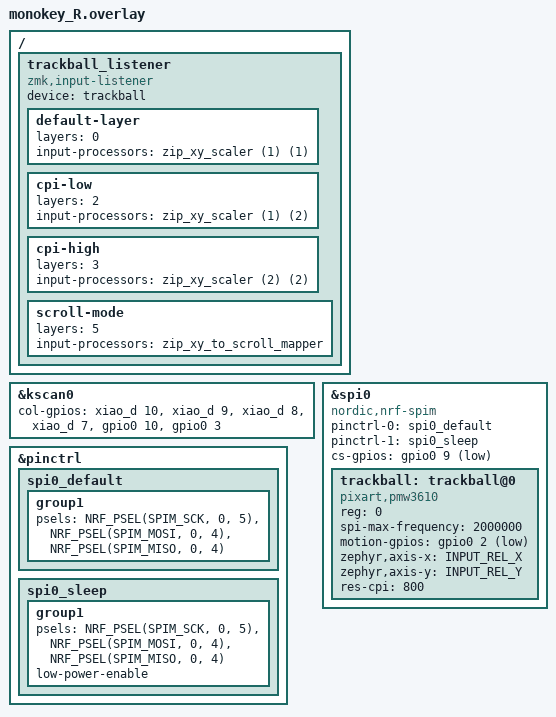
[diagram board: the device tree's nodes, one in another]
#include <zephyr/dt-bindings/input/input-event-codes.h>
#include "monokey.dtsi"

/* =========================
 * Right half: add col-gpios (required by zmk,kscan-gpio-matrix)
 * =========================
 *
 * NOTE:
 * 左側は最後の列に <&gpio0 9 ...> を使っていますが、
 * 右側はSPIトラックボールのCSに gpio0 9 を使っているため競合します。
 *
 * ここでは「ビルドを通すため」に、最後の1本だけ別ピン(gpio0 3)に退避しています。
 * もし右側キーが反応しない場合は、この gpio0 3 を"右側実配線の列ピン"へ変更してください。
 */
&kscan0 {
    col-gpios
        = <&xiao_d 10 GPIO_ACTIVE_HIGH>
        , <&xiao_d 9  GPIO_ACTIVE_HIGH>
        , <&xiao_d 8  GPIO_ACTIVE_HIGH>
        , <&xiao_d 7  GPIO_ACTIVE_HIGH>
        , <&gpio0 10  GPIO_ACTIVE_HIGH>
        , <&gpio0 3   GPIO_ACTIVE_HIGH>
        ;
};

&pinctrl {
    spi0_default: spi0_default {
        group1 {
            psels = <NRF_PSEL(SPIM_SCK, 0, 5)>,
                    <NRF_PSEL(SPIM_MOSI, 0, 4)>,
                    <NRF_PSEL(SPIM_MISO, 0, 4)>;
        };
    };

    spi0_sleep: spi0_sleep {
        group1 {
            psels = <NRF_PSEL(SPIM_SCK, 0, 5)>,
                    <NRF_PSEL(SPIM_MOSI, 0, 4)>,
                    <NRF_PSEL(SPIM_MISO, 0, 4)>;
            low-power-enable;
        };
    };
};

&spi0 {
    status = "okay";
    compatible = "nordic,nrf-spim";

    pinctrl-0 = <&spi0_default>;
    pinctrl-1 = <&spi0_sleep>;
    pinctrl-names = "default", "sleep";

    cs-gpios = <&gpio0 9 GPIO_ACTIVE_LOW>;

    trackball: trackball@0 {
        status = "okay";
        compatible = "pixart,pmw3610";
        reg = <0>;
        spi-max-frequency = <2000000>;
        motion-gpios = <&gpio0 2 (GPIO_ACTIVE_LOW | GPIO_PULL_UP)>;

        /* ✅ 回転補正を外し、素直に X=REL_X / Y=REL_Y */
        zephyr,axis-x = <INPUT_REL_X>;
        zephyr,axis-y = <INPUT_REL_Y>;

        res-cpi = <800>;
    };
};

#include <input/processors.dtsi>

/ {
    trackball_listener {
        compatible = "zmk,input-listener";
        device = <&trackball>;

        /* ✅ 反転も不要なので(1,1)に戻す */
        default-layer {
            layers = <0>;
            input-processors = <&zip_xy_scaler (1) (1)>;
        };

        cpi-low {
            layers = <2>;
            input-processors = <&zip_xy_scaler (1) (2)>;
        };

        cpi-high {
            layers = <3>;
            input-processors = <&zip_xy_scaler (2) (2)>;
        };

        scroll-mode {
            layers = <5>;
            input-processors = <&zip_xy_to_scroll_mapper>;
        };
    };
};
